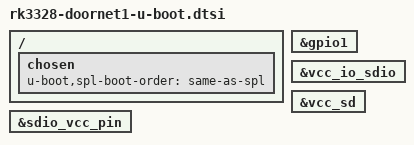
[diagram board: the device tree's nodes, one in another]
// SPDX-License-Identifier: GPL-2.0+

#include "rk3328-u-boot.dtsi"
#include "rk3328-sdram-ddr4-666.dtsi"

/ {
	chosen {
		u-boot,spl-boot-order = "same-as-spl", &sdmmc;
	};
};

&gpio1 {
	bootph-pre-ram;
};

&sdio_vcc_pin {
	bootph-pre-ram;
};

&vcc_io_sdio {
	bootph-pre-ram;
};

&vcc_sd {
	bootph-pre-ram;
};
